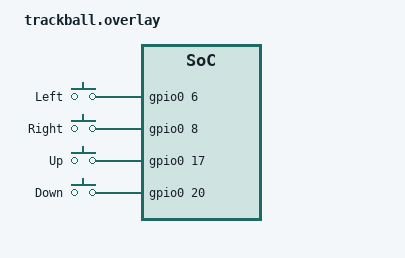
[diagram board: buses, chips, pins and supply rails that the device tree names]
/ {
    trackball: trackball {
        compatible = "gpio-keys";
        left {
            gpios = <&gpio0 6 GPIO_ACTIVE_HIGH>;
            label = "Left";
        };
        right {
            gpios = <&gpio0 8 GPIO_ACTIVE_HIGH>;
            label = "Right";
        };
        up {
            gpios = <&gpio0 17 GPIO_ACTIVE_HIGH>;
            label = "Up";
        };
        down {
            gpios = <&gpio0 20 GPIO_ACTIVE_HIGH>;
            label = "Down";
        };
    };
};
